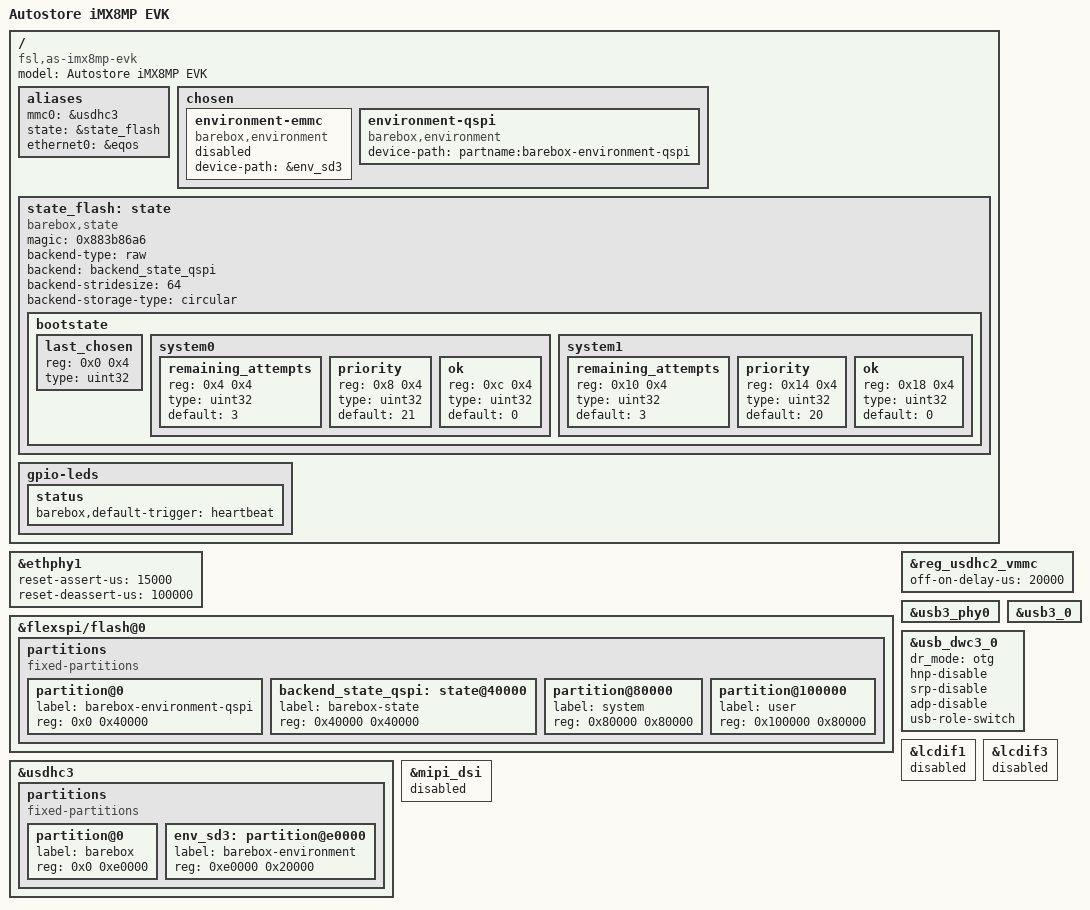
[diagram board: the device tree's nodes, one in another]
// SPDX-License-Identifier: (GPL-2.0 OR MIT)
/*
 * Copyright 2017 NXP
 * Copyright (C) 2017 Pengutronix, Oleksij Rempel <kernel@pengutronix.de>
 */

/dts-v1/;

#include <arm64/freescale/imx8mp-evk.dts>
#include "imx8mp.dtsi"

/ {

	model = "Autostore iMX8MP EVK";
    compatible = "fsl,as-imx8mp-evk", "fsl,imx8mp";

	aliases {
		mmc0 = &usdhc3;
		state = &state_flash;
		ethernet0 = &eqos;
	};

	chosen {
		environment-emmc {
			compatible = "barebox,environment";
			device-path = &env_sd3;
			status = "disabled";
		};
		environment-qspi {
			compatible = "barebox,environment";
			device-path = &{flexspi/flash@0}, "partname:barebox-environment-qspi";
			status = "okay";
		};
	};

	state_flash: state {
		magic = <0x883b86a6>;
		compatible = "barebox,state";
		backend-type = "raw";
		backend = <&backend_state_qspi>;
		backend-stridesize = <64>;
		status = "okay";
		backend-storage-type = "circular";

		#address-cells = <1>;
		#size-cells = <1>;
		bootstate {
			#address-cells = <1>;
			#size-cells = <1>;
			last_chosen {
				reg = <0x0 0x4>;
				type = "uint32";
			};
			system0 {
				#address-cells = <1>;
				#size-cells = <1>;
				remaining_attempts {
					reg = <0x4 0x4>;
					type = "uint32";
					default = <3>;
				};
				priority {
					reg = <0x8 0x4>;
					type = "uint32";
					default = <21>;
				};
				ok {
					reg = <0xc 0x4>;
					type = "uint32";
					default = <0>;
				};
			};
			system1 {
				#address-cells = <1>;
				#size-cells = <1>;
				remaining_attempts {
					reg = <0x10 0x4>;
					type = "uint32";
					default = <3>;
				};
				priority {
					reg = <0x14 0x4>;
					type = "uint32";
					default = <20>;
				};
				ok {
					reg = <0x18 0x4>;
					type = "uint32";
					default = <0>;
				};
			};
		};
	};

	gpio-leds {
		status {
			barebox,default-trigger = "heartbeat";
		};
	};
};

/delete-node/ &{/memory@40000000};

&ethphy1 {
	reset-assert-us = <15000>;
	reset-deassert-us = <100000>;
};

&{flexspi/flash@0} {
		partitions {
		compatible = "fixed-partitions";
		#address-cells = <1>;
		#size-cells = <1>;

		partition@0 {
			label = "barebox-environment-qspi";
			reg = <0x0 0x40000>;
		};

		backend_state_qspi: state@40000 {
			label = "barebox-state";
			reg = <0x40000 0x40000>;
		};

		partition@80000 {
			label = "system";
			reg = <0x80000 0x80000>;
		};
		partition@100000 {
			label = "user";
			reg = <0x100000 0x80000>;
		};

	};
};

&reg_usdhc2_vmmc {
	off-on-delay-us = <20000>;
};

&usb3_phy0 {
	status = "okay";
};

&usb3_0 {
	status = "okay";
};

&usb_dwc3_0 {
	dr_mode = "otg";
	hnp-disable;
	srp-disable;
	adp-disable;
	usb-role-switch;
	status = "okay";
};

&usdhc3 {
	#address-cells = <1>;
	#size-cells = <1>;

	partitions {
		compatible = "fixed-partitions";
		#size-cells = <1>;
		#address-cells = <1>;
		partition@0 {
			label = "barebox";
			reg = <0x0 0xe0000>;
		};

		env_sd3: partition@e0000 {
			label = "barebox-environment";
			reg = <0xe0000 0x20000>;
		};
	};
};

&lcdif1 {
	status = "disabled";
};

&lcdif3 {
	status = "disabled";
};

&mipi_dsi {
	status = "disabled";
};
